VERSION ""

NS_ :

BS_:

BU_: PC PSI9040_40
VAL_TABLE_ Read_Status_Alarm_REM_SB 1 "on" 0 "off" ;
VAL_TABLE_ Read_Status_Function_Mode 1 "on" 0 "off" ;
VAL_TABLE_ Read_Coil_DC_After_Power_On 65535 "off" 65534 "restore" ;
VAL_TABLE_ Read_Coil_DC_After_PF_Alarm 65280 "auto-on" 0 "off" ;
VAL_TABLE_ Send_Coil_DC_After_Power_On 65535 "off" 65534 "restore" ;
VAL_TABLE_ Send_Coil_DC_After_PF_Alarm 65280 "auto-on" 0 "off" ;
VAL_TABLE_ Send_Coil_Remote_On_Off 65280 "on" 0 "off" ;
VAL_TABLE_ Read_Status_Function_Mode_Cyc 1 "on" 0 "off" ;
VAL_TABLE_ Read_Status_Alarm_REM_SB_Cyc 1 "on" 0 "off" ;
VAL_TABLE_ Send_Coil_Remote_On_Off_Cyc 1 "on" 0 "off" ;

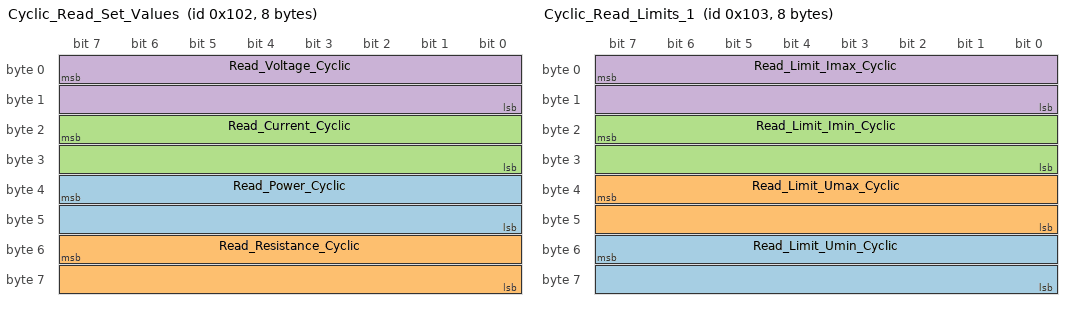
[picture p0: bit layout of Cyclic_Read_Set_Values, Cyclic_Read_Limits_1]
BO_ 258 Cyclic_Read_Set_Values: 8 PSI9040_40
 SG_ Read_Power_Cyclic : 39|16@0+ (0.019073777,0) [0|1020] "W"  PC
 SG_ Read_Resistance_Cyclic : 55|16@0+ (0.000572213,0) [0|30.6] "Ohm"  PC
 SG_ Read_Current_Cyclic : 23|16@0+ (0.000762951,0) [0|40.8] "A"  PC
 SG_ Read_Voltage_Cyclic : 7|16@0+ (0.000762951,0) [0|40.8] "V"  PC

BO_ 260 Cyclic_Read_Limits_2: 8 PSI9040_40
 SG_ Read_Limit_Rmax_Cyclic : 23|16@0+ (0.000572213,0) [0|30.6] "Ohm"  PC
 SG_ Read_Limit_Pmax_Cyclic : 7|16@0+ (0.019073777,0) [0|1020] "W"  PC

BO_ 259 Cyclic_Read_Limits_1: 8 PSI9040_40
 SG_ Read_Limit_Umin_Cyclic : 55|16@0+ (0.000762951,0) [0|40.8] "V"  PC
 SG_ Read_Limit_Umax_Cyclic : 39|16@0+ (0.000762951,0) [0|40.8] "V"  PC
 SG_ Read_Limit_Imin_Cyclic : 23|16@0+ (0.000762951,0) [0|40.8] "A"  PC
 SG_ Read_Limit_Imax_Cyclic : 7|16@0+ (0.000762951,0) [0|40.8] "A"  PC

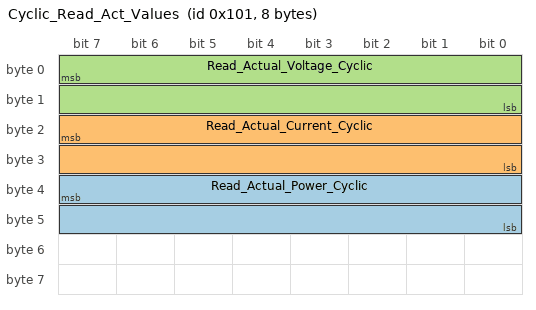
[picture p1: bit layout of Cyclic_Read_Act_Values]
BO_ 257 Cyclic_Read_Act_Values: 8 PSI9040_40
 SG_ Read_Actual_Power_Cyclic : 39|16@0+ (0.019073777,0) [0|1020] "W"  PC
 SG_ Read_Actual_Current_Cyclic : 23|16@0+ (0.000762951,0) [0|40.8] "A"  PC
 SG_ Read_Actual_Voltage_Cyclic : 7|16@0+ (0.000762951,0) [0|40.8] "V"  PC

BA_DEF_ SG_  "GenSigStartValue" INT -2147483648 2147483647;
BA_DEF_ SG_  "GenSigSendType" ENUM  "Cyclic","OnWrite","OnWriteWithRepetition","OnChange","OnChangeWithRepetition","IfActive","IfActiveWithRepetition","NoSigSendType";
BA_DEF_ SG_  "GenSigEnvVarType" ENUM  "int","float","undef";
BA_DEF_ BO_  "GenMsgSendType" ENUM  "cyclicX","spontanX","cyclicIfActiveX","spontanWithDelay","cyclicAndSpontanX","cyclicAndSpontanWithDelay","spontanWithRepetition","cyclicIfActiveAndSpontanWD","cyclicIfActiveFast","cyclicWithRepeatOnDemand";
BA_DEF_ BO_  "GenMsgILSupport" ENUM  "No","Yes";
BA_DEF_ BO_  "GenMsgCycleTime" INT 0 65535;
BA_DEF_ BO_  "GenMsgAutoGenSnd" ENUM  "No","Yes";
BA_DEF_ BO_  "GenMsgAutoGenDsp" ENUM  "No","Yes";
BA_DEF_ BU_  "iLUsed" ENUM  "No","Yes";
BA_DEF_ BU_  "GenNodAutoGenSnd" ENUM  "No","Yes";
BA_DEF_ BU_  "GenNodAutoGenDsp" ENUM  "No","Yes";
BA_DEF_  "DBName" STRING ;
BA_DEF_  "BusType" STRING ;
BA_DEF_  "Baudrate" INT 0 1000000;
BA_DEF_DEF_  "GenSigStartValue" 0;
BA_DEF_DEF_  "GenSigSendType" "Cyclic";
BA_DEF_DEF_  "GenSigEnvVarType" "undef";
BA_DEF_DEF_  "GenMsgSendType" "cyclicX";
BA_DEF_DEF_  "GenMsgILSupport" "Yes";
BA_DEF_DEF_  "GenMsgCycleTime" 100;
BA_DEF_DEF_  "GenMsgAutoGenSnd" "Yes";
BA_DEF_DEF_  "GenMsgAutoGenDsp" "Yes";
BA_DEF_DEF_  "iLUsed" "Yes";
BA_DEF_DEF_  "GenNodAutoGenSnd" "Yes";
BA_DEF_DEF_  "GenNodAutoGenDsp" "Yes";
BA_DEF_DEF_  "DBName" "";
BA_DEF_DEF_  "BusType" "";
BA_DEF_DEF_  "Baudrate" 500000;
BA_ "BusType" "CAN";
BA_ "DBName" "PSI9000";
BA_ "GenMsgSendType" BO_ 258 1;
BA_ "GenMsgCycleTime" BO_ 258 1000;
BA_ "GenMsgSendType" BO_ 260 1;
BA_ "GenMsgCycleTime" BO_ 260 1000;
BA_ "GenMsgSendType" BO_ 259 1;
BA_ "GenMsgCycleTime" BO_ 259 1000;
BA_ "GenMsgSendType" BO_ 257 1;
BA_ "GenMsgCycleTime" BO_ 257 20;
